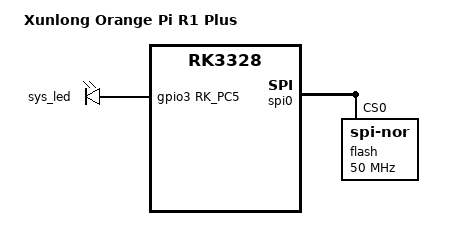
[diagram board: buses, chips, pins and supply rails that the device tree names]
// SPDX-License-Identifier: (GPL-2.0+ OR MIT)
#include "rk3328-nanopi-r2s.dts"

/ {
	model = "Xunlong Orange Pi R1 Plus";
	compatible = "xunlong,orangepi-r1-plus", "rockchip,rk3328";
};

&spi0 {
	status = "okay";

	flash@0 {
		compatible = "jedec,spi-nor";
		reg = <0>;
		spi-max-frequency = <50000000>;
	};
};

&sys_led {
	gpios = <&gpio3 RK_PC5 GPIO_ACTIVE_HIGH>;
};

&sys_led_pin {
	rockchip,pins = <3 RK_PC5 RK_FUNC_GPIO &pcfg_pull_none>;
};
